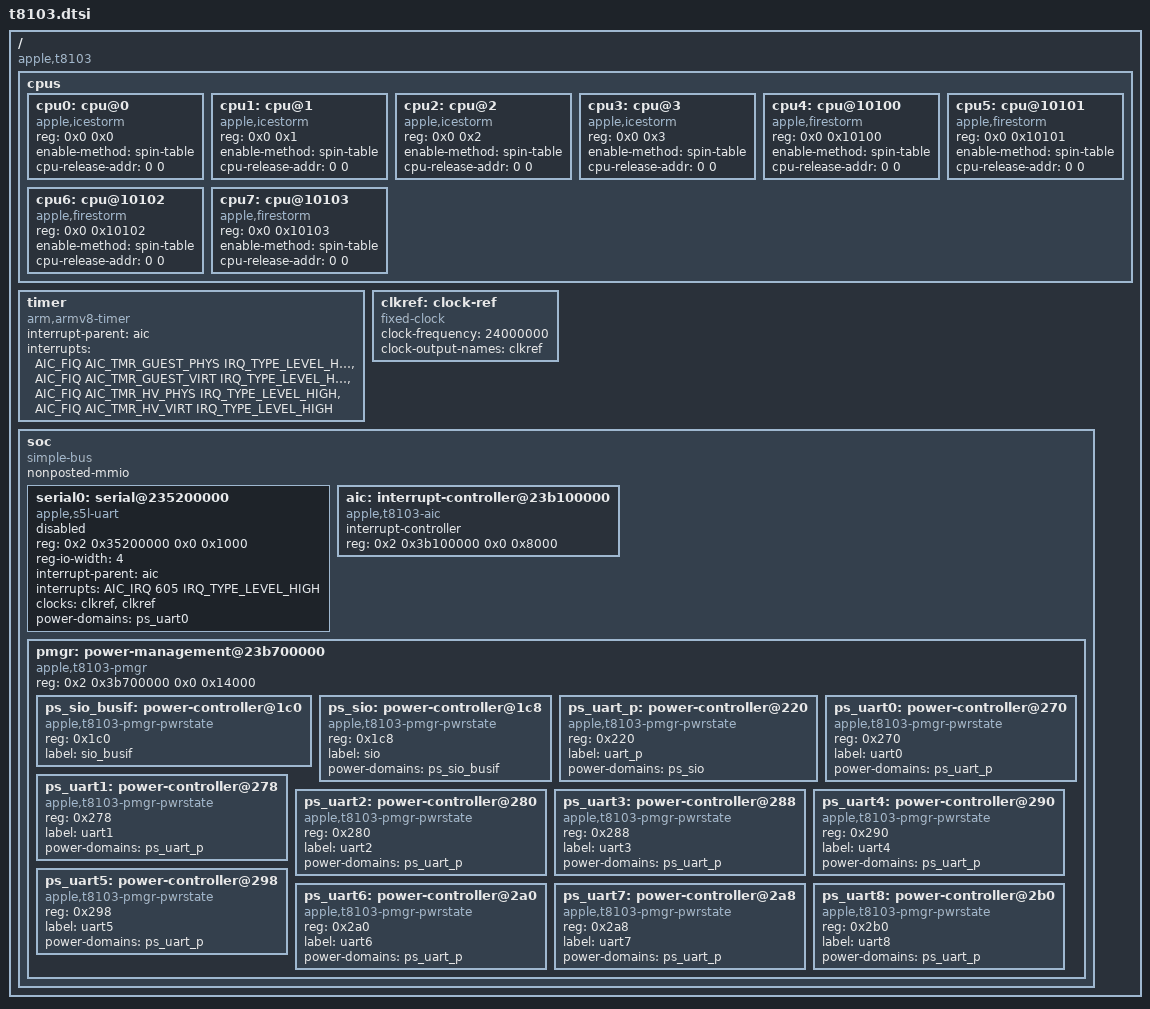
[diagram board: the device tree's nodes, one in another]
// SPDX-License-Identifier: GPL-2.0+ OR MIT
/*
 * Apple T8103 "M1" SoC
 *
 * Other names: H13G, "Tonga"
 *
 * Copyright The Asahi Linux Contributors
 */

#include <dt-bindings/interrupt-controller/apple-aic.h>
#include <dt-bindings/interrupt-controller/irq.h>

/ {
	compatible = "apple,t8103", "apple,arm-platform";

	#address-cells = <2>;
	#size-cells = <2>;

	cpus {
		#address-cells = <2>;
		#size-cells = <0>;

		cpu0: cpu@0 {
			compatible = "apple,icestorm";
			device_type = "cpu";
			reg = <0x0 0x0>;
			enable-method = "spin-table";
			cpu-release-addr = <0 0>; /* To be filled by loader */
		};

		cpu1: cpu@1 {
			compatible = "apple,icestorm";
			device_type = "cpu";
			reg = <0x0 0x1>;
			enable-method = "spin-table";
			cpu-release-addr = <0 0>; /* To be filled by loader */
		};

		cpu2: cpu@2 {
			compatible = "apple,icestorm";
			device_type = "cpu";
			reg = <0x0 0x2>;
			enable-method = "spin-table";
			cpu-release-addr = <0 0>; /* To be filled by loader */
		};

		cpu3: cpu@3 {
			compatible = "apple,icestorm";
			device_type = "cpu";
			reg = <0x0 0x3>;
			enable-method = "spin-table";
			cpu-release-addr = <0 0>; /* To be filled by loader */
		};

		cpu4: cpu@10100 {
			compatible = "apple,firestorm";
			device_type = "cpu";
			reg = <0x0 0x10100>;
			enable-method = "spin-table";
			cpu-release-addr = <0 0>; /* To be filled by loader */
		};

		cpu5: cpu@10101 {
			compatible = "apple,firestorm";
			device_type = "cpu";
			reg = <0x0 0x10101>;
			enable-method = "spin-table";
			cpu-release-addr = <0 0>; /* To be filled by loader */
		};

		cpu6: cpu@10102 {
			compatible = "apple,firestorm";
			device_type = "cpu";
			reg = <0x0 0x10102>;
			enable-method = "spin-table";
			cpu-release-addr = <0 0>; /* To be filled by loader */
		};

		cpu7: cpu@10103 {
			compatible = "apple,firestorm";
			device_type = "cpu";
			reg = <0x0 0x10103>;
			enable-method = "spin-table";
			cpu-release-addr = <0 0>; /* To be filled by loader */
		};
	};

	timer {
		compatible = "arm,armv8-timer";
		interrupt-parent = <&aic>;
		interrupt-names = "phys", "virt", "hyp-phys", "hyp-virt";
		interrupts = <AIC_FIQ AIC_TMR_GUEST_PHYS IRQ_TYPE_LEVEL_HIGH>,
			     <AIC_FIQ AIC_TMR_GUEST_VIRT IRQ_TYPE_LEVEL_HIGH>,
			     <AIC_FIQ AIC_TMR_HV_PHYS IRQ_TYPE_LEVEL_HIGH>,
			     <AIC_FIQ AIC_TMR_HV_VIRT IRQ_TYPE_LEVEL_HIGH>;
	};

	clkref: clock-ref {
		compatible = "fixed-clock";
		#clock-cells = <0>;
		clock-frequency = <24000000>;
		clock-output-names = "clkref";
	};

	soc {
		compatible = "simple-bus";
		#address-cells = <2>;
		#size-cells = <2>;

		ranges;
		nonposted-mmio;

		serial0: serial@235200000 {
			compatible = "apple,s5l-uart";
			reg = <0x2 0x35200000 0x0 0x1000>;
			reg-io-width = <4>;
			interrupt-parent = <&aic>;
			interrupts = <AIC_IRQ 605 IRQ_TYPE_LEVEL_HIGH>;
			/*
			 * TODO: figure out the clocking properly, there may
			 * be a third selectable clock.
			 */
			clocks = <&clkref>, <&clkref>;
			clock-names = "uart", "clk_uart_baud0";
			power-domains = <&ps_uart0>;
			status = "disabled";
		};

		aic: interrupt-controller@23b100000 {
			compatible = "apple,t8103-aic", "apple,aic";
			#interrupt-cells = <3>;
			interrupt-controller;
			reg = <0x2 0x3b100000 0x0 0x8000>;
		};

		pmgr: power-management@23b700000 {
			compatible = "apple,t8103-pmgr", "apple,pmgr", "syscon", "simple-mfd";
			#address-cells = <1>;
			#size-cells = <0>;

			reg = <0x2 0x3b700000 0x0 0x14000>;

			ps_sio_busif: power-controller@1c0 {
				compatible = "apple,t8103-pmgr-pwrstate", "apple,pmgr-pwrstate";
				reg = <0x1c0>;
				#power-domain-cells = <0>;
				#reset-cells = <0>;
				label = "sio_busif";
			};

			ps_sio: power-controller@1c8 {
				compatible = "apple,t8103-pmgr-pwrstate", "apple,pmgr-pwrstate";
				reg = <0x1c8>;
				#power-domain-cells = <0>;
				#reset-cells = <0>;
				label = "sio";
				power-domains = <&ps_sio_busif>;
			};

			ps_uart_p: power-controller@220 {
				compatible = "apple,t8103-pmgr-pwrstate", "apple,pmgr-pwrstate";
				reg = <0x220>;
				#power-domain-cells = <0>;
				#reset-cells = <0>;
				label = "uart_p";
				power-domains = <&ps_sio>;
			};

			ps_uart0: power-controller@270 {
				compatible = "apple,t8103-pmgr-pwrstate", "apple,pmgr-pwrstate";
				reg = <0x270>;
				#power-domain-cells = <0>;
				#reset-cells = <0>;
				label = "uart0";
				power-domains = <&ps_uart_p>;
			};

			ps_uart1: power-controller@278 {
				compatible = "apple,t8103-pmgr-pwrstate", "apple,pmgr-pwrstate";
				reg = <0x278>;
				#power-domain-cells = <0>;
				#reset-cells = <0>;
				label = "uart1";
				power-domains = <&ps_uart_p>;
			};

			ps_uart2: power-controller@280 {
				compatible = "apple,t8103-pmgr-pwrstate", "apple,pmgr-pwrstate";
				reg = <0x280>;
				#power-domain-cells = <0>;
				#reset-cells = <0>;
				label = "uart2";
				power-domains = <&ps_uart_p>;
			};

			ps_uart3: power-controller@288 {
				compatible = "apple,t8103-pmgr-pwrstate", "apple,pmgr-pwrstate";
				reg = <0x288>;
				#power-domain-cells = <0>;
				#reset-cells = <0>;
				label = "uart3";
				power-domains = <&ps_uart_p>;
			};

			ps_uart4: power-controller@290 {
				compatible = "apple,t8103-pmgr-pwrstate", "apple,pmgr-pwrstate";
				reg = <0x290>;
				#power-domain-cells = <0>;
				#reset-cells = <0>;
				label = "uart4";
				power-domains = <&ps_uart_p>;
			};

			ps_uart5: power-controller@298 {
				compatible = "apple,t8103-pmgr-pwrstate", "apple,pmgr-pwrstate";
				reg = <0x298>;
				#power-domain-cells = <0>;
				#reset-cells = <0>;
				label = "uart5";
				power-domains = <&ps_uart_p>;
			};

			ps_uart6: power-controller@2a0 {
				compatible = "apple,t8103-pmgr-pwrstate", "apple,pmgr-pwrstate";
				reg = <0x2a0>;
				#power-domain-cells = <0>;
				#reset-cells = <0>;
				label = "uart6";
				power-domains = <&ps_uart_p>;
			};

			ps_uart7: power-controller@2a8 {
				compatible = "apple,t8103-pmgr-pwrstate", "apple,pmgr-pwrstate";
				reg = <0x2a8>;
				#power-domain-cells = <0>;
				#reset-cells = <0>;
				label = "uart7";
				power-domains = <&ps_uart_p>;
			};

			ps_uart8: power-controller@2b0 {
				compatible = "apple,t8103-pmgr-pwrstate", "apple,pmgr-pwrstate";
				reg = <0x2b0>;
				#power-domain-cells = <0>;
				#reset-cells = <0>;
				label = "uart8";
				power-domains = <&ps_uart_p>;
			};
		};
	};
};
